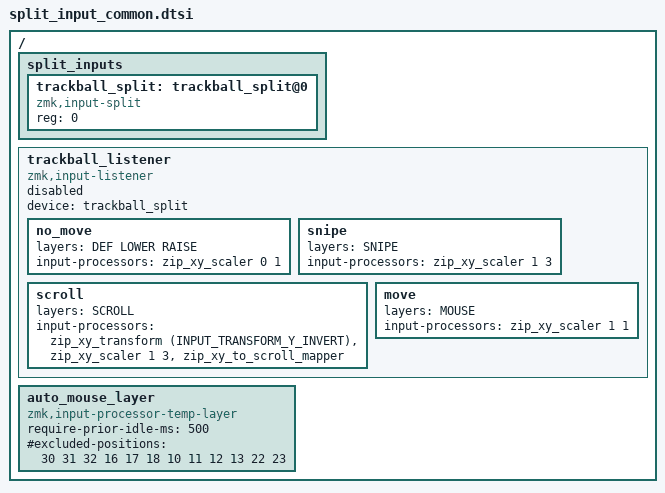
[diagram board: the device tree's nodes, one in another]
#include <dt-bindings/zmk/input_transform.h>
#include <input/processors.dtsi>

#define DEF 0
#define MOUSE 1
#define LOWER 2
#define RAISE 3
#define SCROLL 4
#define SNIPE 5

/ {
  split_inputs {
    #address-cells = <1>;
    #size-cells = <0>;

    trackball_split: trackball_split@0 {
      compatible = "zmk,input-split";
      reg = <0>;
    };
  };

  trackball_listener: trackball_listener {
    compatible = "zmk,input-listener";
    status = "disabled";
    device = <&trackball_split>;
	
	no_move {
      layers = <DEF LOWER RAISE>;
      input-processors = <&zip_xy_scaler 0 1>;
    };

    snipe {
      layers = <SNIPE>;
      input-processors = <&zip_xy_scaler 1 3>;
    };

    scroll {
      layers = <SCROLL>;
      input-processors = <&zip_xy_transform (INPUT_TRANSFORM_Y_INVERT)>, <&zip_xy_scaler 1 3>, <&zip_xy_to_scroll_mapper>;
    };

    move {
      layers = <MOUSE>;
	  input-processors = <&zip_xy_scaler 1 1>;
    };
  };

  auto_mouse_layer: auto_mouse_layer {
    compatible = "zmk,input-processor-temp-layer";
    #input-processor-cells = <2>;
    require-prior-idle-ms = <500>;
    #excluded-positions = <30 31 32 16 17 18 10 11 12 13 22 23>;
  };
};
